# NUC123AE_v1 register map
File version: 1.0
Registers are 32-bit, read-write, reset 0x0 unless marked. A register's access mark holds for its fields unless they carry their own. Offsets are from the block's base; [hi:lo] are bit positions; lines under a group give offsets from that group; {n}, {i} and the like mark numbered series; 'fields as' and 'values as' point back to an identical list.

## PWMA — PWMA Register Map
Base 0x40040000
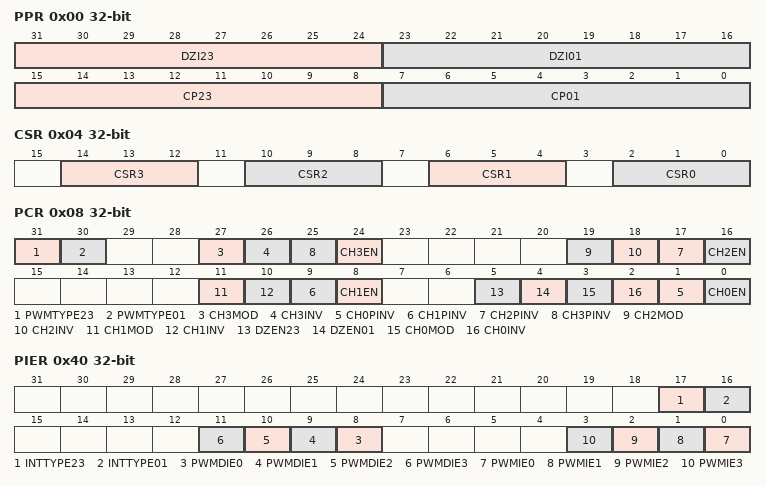
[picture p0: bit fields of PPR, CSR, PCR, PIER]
0x00 PPR — PWM Group A Pre-scale Register
  [31:24] DZI23 — Dead-zone Interval for Pair of Channel2 and Channel3 (PWM2 and PWM3 Pair for PWM Group A). These 8 bits determine dead-zone length. The unit time of dead-zone length is received from corresponding CSR bits.
  [23:16] DZI01 — Dead-zone Interval for Pair of Channel 0 and Channel 1 (PWM0 and PWM1 Pair for PWM Group A). These 8 bits determine dead-zone length. The unit time of dead-zone length is received from corresponding CSR bits.
  [15:8] CP23 — Clock Prescaler 2 (PWM Timer2 / 3 for Group A). Clock input is divided by (CP23 + 1) before it is fed to the corresponding PWM-timer.
  [7:0] CP01 — Clock Prescaler 0 (PWM-timer 0 / 1 for Group A). Clock input is divided by (CP01 + 1) before it is fed to the corresponding PWM-timer.
0x04 CSR — PWM Group A Clock Selector Register
  [14:12] CSR3 — PWM Timer 3 Clock Source Selection (PWM timer 3 for group A and PWM timer 7 for group B)
  [10:8] CSR2 — PWM Timer 2 Clock Source Selection (PWM Timer 2 for Group A and PWM Timer 6 for Group B). Select clock input for PWM timer. (Table is the same as CSR3.)
  [6:4] CSR1 — PWM Timer 1 Clock Source Selection (PWM Timer 1 for Group A and PWM Timer 5 for Group B). Select clock input for PWM timer. (Table is the same as CSR3.)
  [2:0] CSR0 — PWM Timer 0 Clock Source Selection (PWM Timer 0 for Group A and PWM Timer 4 for Group B). Select clock input for PWM timer. (Table is the same as CSR3.)
0x08 PCR — PWM Group A Control Register
  [31] PWMTYPE23 — PWM23 Aligned Type Selection Bit (PWM2 and PWM3 Pair for PWM Group A)
    0=Edge-aligned type; 1=Center-aligned type
  [30] PWMTYPE01 — PWM01 Aligned Type Selection Bit (PWM0 and PWM1 Pair for PWM Group A)
    0=Edge-aligned type; 1=Center-aligned type
  [27] CH3MOD — PWM-Timer 3 Auto-reload/One-Shot Mode (PWM Timer 3 for Group A). Note: If there is a transition at this bit, it will cause CNR3 and CMR3 be clear.
    0=One-shot mode; 1=Auto-reload mode
  [26] CH3INV — PWM-Timer 3 Output Inverter Enable (PWM Timer 3 for Group A)
    0=Inverter Disabled; 1=Inverter Enabled
  [8n+1] CH{n}PINV (n=0..3) — PWM-Timer {n} Output Polar Inverse Enable (PWM Timer {n} for Group A)
    0=PWM{n} output polar inverse Disabled; 1=PWM{n} output polar inverse Enabled
  [24] CH3EN — PWM-Timer 3 Enable (PWM Timer 3 for Group A)
    0=Corresponding PWM-Timer Running Stopped; 1=Corresponding PWM-Timer Start Run Enabled
  [19] CH2MOD — PWM-Timer 2 Auto-reload/One-Shot Mode (PWM Timer 2 for Group A). Note: If there is a transition at this bit, it will cause CNR2 and CMR2 be clear.
    0=One-shot mode; 1=Auto-reload mode
  [18] CH2INV — PWM-Timer 2 Output Inverter Enable (PWM Timer 2 for Group A)
    0=Inverter Disabled; 1=Inverter Enabled
  [16] CH2EN — PWM-Timer 2 Enable (PWM Timer 2 for Group A)
    values as CH3EN
  [11] CH1MOD — PWM-Timer 1 Auto-reload/One-Shot Mode (PWM Timer 1 for Group A). Note: If there is a transition at this bit, it will cause CNR1 and CMR1 be clear.
    0=One-shot mode; 1=Auto-load mode
  [10] CH1INV — PWM-Timer 1 Output Inverter Enable (PWM Timer 1 for Group A and PWM Timer 5 for Group B)
    0=Inverter Disabled; 1=Inverter Enabled
  [8] CH1EN — PWM-Timer 1 Enable (PWM Timer 1 for Group A and PWM Timer 5 for Group B)
    values as CH3EN
  [5] DZEN23 — Dead-Zone 2 Generator Enable (PWM2 and PWM3 Pair for PWM Group A). Note: When dead-zone generator is enabled, the pair of PWM2 and PWM3 becomes a complementary pair for PWM group A and the pair of PWM6 and PWM7 becomes a complementary pair for PWM group B.
    0=Disabled; 1=Enabled
  [4] DZEN01 — Dead-Zone 0 Generator Enable (PWM0 and PWM1 Pair for PWM Group A ). Note: When dead-zone generator is enabled, the pair of PWM0 and PWM1 becomes a complementary pair for PWM group A.
    0=Disabled; 1=Enabled
  [3] CH0MOD — PWM-Timer 0 Auto-reload/One-Shot Mode (PWM Timer 0 for Group A). Note: If there is a transition at this bit, it will cause CNR0 and CMR0 be clear.
    0=One-shot mode; 1=Auto-reload mode
  [2] CH0INV — PWM-Timer 0 Output Inverter Enable (PWM Timer 0 for Group A)
    0=Inverter Disabled; 1=Inverter Enabled
  [0] CH0EN — PWM-Timer 0 Enable (PWM timer 0 for group A)
    values as CH3EN
{0xC+0xC*i} CNR{i} (i=0..3) — PWM Group A Counter Register {i}
  [15:0] CNRx — PWM Timer Loaded Value. CNR determines the PWM period. Note: Any write to CNR will take effect in the next PWM cycle. Note: When PWM operating at center-aligned type, CNR value should be set between 0x0000 to 0xFFFE. If CNR equal to 0xFFFF, the PWM will work unpredictable. Note: When CNR value is set to 0, PWM output is always high.
{0x10+0xC*i} CMR{i} (i=0..3) — PWM Group A Comparator Register {i}
  [15:0] CMRx — PWM Comparator Register. CMR determines the PWM duty. Note: Any write to CNR will take effect in the next PWM cycle.
{0x14+0xC*i} PDR{i} ro (i=0..3) — PWM Group A Data Register {i}
  [15:0] PDRx — PWM Data Register. User can monitor PDR to know the current value in 16-bit down counter.
0x3C PBCR — PWM Group A backward compatible Register
0x40 PIER — PWM Group A Interrupt Enable Register
  [17] INTTYPE23 — PWM12 Interrupt Type Selection Bit (PWM2 and PWM3 Pair for PWM Group A, PWM6 and PWM7 Pair for PWM Group B). Note: This bit is effective when PWM in central align mode only.
    0=PWMIFn will be set if PWM counter underflow; 1=PWMIFn will be set if PWM counter matches CNRn register
  [16] INTTYPE01 — PWM01 Interrupt Type Selection Bit (PWM0 and PWM1 Pair for PWM Group A). Note: This bit is effective when PWM in central align mode only.
    values as INTTYPE23
  [n+8] PWMDIE{n} (n=0..3) — PWM Channel {n} Duty Interrupt Enable
    0=Disabled; 1=Enabled
  [n] PWMIE{n} (n=0..3) — PWM Channel {n} Interrupt Enable
    0=Disabled; 1=Enabled
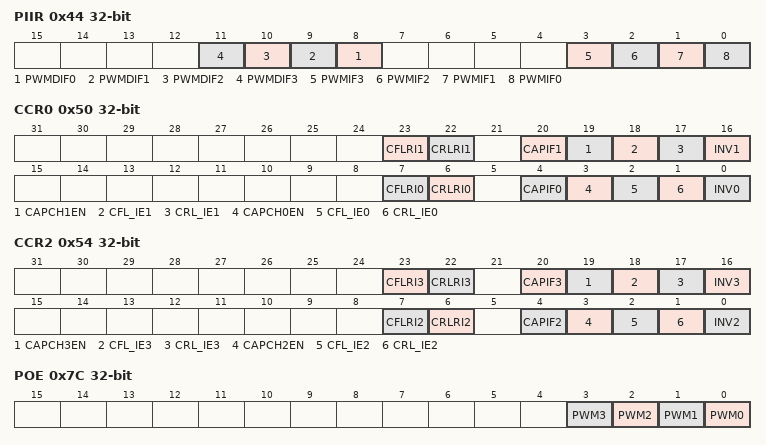
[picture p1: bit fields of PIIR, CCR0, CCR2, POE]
0x44 PIIR — PWM Group A Interrupt Indication Register
  [n+8] PWMDIF{n} (n=0..3) — PWM channel {n} Duty Interrupt Flag. Flag is set by hardware when channel {n} PWM counter down count and reaches CMR{n}, software can clear this bit by writing a one to it. Note: If CMR is equal to CNR, this flag is not working
  [3] PWMIF3 — PWM channel 3 Interrupt Status. This bit is set by hardware when PWM3 counter reaches the requirement of interrupt (depending on INTTYPE23 bit of PIER register) if PWM3 interrupt enable bit (PWMIE3) is 1, software can write 1 to clear this bit to zero
  [2] PWMIF2 — PWM channel 2 Interrupt Status. This bit is set by hardware when PWM2 counter reaches the requirement of interrupt (depending on INTTYPE23 bit of PIER register) if PWM2 interrupt enable bit (PWMIE2) is 1, software can write 1 to clear this bit to zero
  [1] PWMIF1 — PWM channel 1 Interrupt Status. This bit is set by hardware when PWM1 counter reaches the requirement of interrupt (depending on INTTYPE01 bit of PIER register) if PWM1 interrupt enable bit (PWMIE1) is 1, software can write 1 to clear this bit to zero
  [0] PWMIF0 — PWM channel 0 Interrupt Status. This bit is set by hardware when PWM0 counter reaches the requirement of interrupt (depending on INTTYPE01 bit of PIER register) if PWM0 interrupt enable bit (PWMIE0) is 1, software can write 1 to clear this bit to zero
0x50 CCR0 — PWM Group A Capture Control Register 0
  [23] CFLRI1 — CFLR1 Latched Indicator Bit. When PWM group input channel 1 has a falling transition, CFLR1 is latched with the value of PWM down-counter and this bit is set by hardware. Software can write 1 to clear this bit to zero.
  [22] CRLRI1 — CRLR1 Latched Indicator Bit. When PWM group input channel 1 has a rising transition, CRLR1 is latched with the value of PWM down-counter and this bit is set by hardware. Software can write 1 to clear this bit to zero.
  [20] CAPIF1 — Channel 1 Capture Interrupt Indication Flag. Write 1 to clear this bit to zero
  [19] CAPCH1EN — Channel 1 Capture Function Enable. When Enabled, Capture latched the PWM-counter and saved to CRLR (Rising latch) and CFLR (Falling latch). When Disabled, Capture does not update CRLR and CFLR, and disable PWM group channel 1 Interrupt.
    0=Capture function on PWM group channel 1 Disabled; 1=Capture function on PWM group channel 1 Enabled
  [18] CFL_IE1 — Channel 1 Falling Latch Interrupt Enable. When Enabled, if Capture detects PWM group channel 1 has falling transition, capture issues an Interrupt.
    0=Falling latch interrupt Disabled; 1=Falling latch interrupt Enabled
  [17] CRL_IE1 — Channel 1 Rising Latch Interrupt Enable. When Enable, if Capture detects PWM group channel 1 has rising transition, capture issues an Interrupt.
    0=Rising latch interrupt Disabled; 1=Rising latch interrupt Enabled
  [16] INV1 — Channel 1 Inverter Enable
    0=Inverter Disabled; 1=Inverter Enabled. Reverse the input signal from GPIO before fed to Capture timer
  [7] CFLRI0 — CFLR0 Latched Indicator Bit. When PWM group input channel 0 has a falling transition, CFLR0 was latched with the value of PWM down-counter and this bit is set by hardware. Software can write 1 to clear this bit to zero.
  [6] CRLRI0 — CRLR0 Latched Indicator Bit. When PWM group input channel 0 has a rising transition, CRLR0 was latched with the value of PWM down-counter and this bit is set by hardware. Software can write 1 to clear this bit to zero.
  [4] CAPIF0 — Channel 0 Capture Interrupt Indication Flag. Write 1 to clear this bit to zero
  [3] CAPCH0EN — Channel 0 Capture Function Enable. When Enabled, Capture latched the PWM-counter value and saved to CRLR (Rising latch) and CFLR (Falling latch). When Disabled, capture does not update CRLR and CFLR, and disable PWM group channel 0 Interrupt.
    0=Capture function on PWM group channel 0 Disabled; 1=Capture function on PWM group channel 0 Enabled
  [2] CFL_IE0 — Channel 0 Falling Latch Interrupt Enable. When Enabled, if capture detects PWM group channel 0 has falling transition, capture issues an Interrupt.
    values as CFL_IE1
  [1] CRL_IE0 — Channel 0 Rising Latch Interrupt Enable. When Enabled, if capture detects PWM group channel 0 has rising transition, capture issues an Interrupt.
    values as CRL_IE1
  [0] INV0 — Channel 0 Inverter Enable
    values as INV1
0x54 CCR2 — PWM Group A Capture Control Register 2
  [23] CFLRI3 — CFLR3 Latched Indicator Bit. When PWM group input channel 3 has a falling transition, CFLR3 was latched with the value of PWM down-counter and this bit is set by hardware. Software can write 1 to clear this bit to zero.
  [22] CRLRI3 — CRLR3 Latched Indicator Bit. When PWM group input channel 3 has a rising transition, CRLR3 was latched with the value of PWM down-counter and this bit is set by hardware. Software can write 1 to clear this bit to zero.
  [20] CAPIF3 — Channel 3 Capture Interrupt Indication Flag. Write 1 to clear this bit to zero
  [19] CAPCH3EN — Channel 3 Capture Function Enable. When Enabled, capture latched the PWM-counter and saved to CRLR (Rising latch) and CFLR (Falling latch). When Disabled, capture does not update CRLR and CFLR, and disable PWM group channel 3 Interrupt.
    0=Capture function on PWM group channel 3 Disabled; 1=Capture function on PWM group channel 3 Enabled
  [18] CFL_IE3 — Channel 3 Falling Latch Interrupt Enable. When Enabled, if capture detects PWM group channel 3 has falling transition, capture issues an Interrupt.
    values as CCR0.CFL_IE1
  [17] CRL_IE3 — Channel 3 Rising Latch Interrupt Enable. When Enabled, if Capture detects PWM group channel 3 has rising transition, capture issues an Interrupt.
    values as CCR0.CRL_IE1
  [16] INV3 — Channel 3 Inverter Enable
    values as CCR0.INV1
  [7] CFLRI2 — CFLR2 Latched Indicator Bit. When PWM group input channel 2 has a falling transition, CFLR2 was latched with the value of PWM down-counter and this bit is set by hardware. Software can write 1 to clear this bit to zero.
  [6] CRLRI2 — CRLR2 Latched Indicator Bit. When PWM group input channel 2 has a rising transition, CRLR2 was latched with the value of PWM down-counter and this bit is set by hardware. Software can write 1 to clear this bit to zero.
  [4] CAPIF2 — Channel 2 Capture Interrupt Indication Flag. Write 1 to clear this bit to zero
  [3] CAPCH2EN — Channel 2 Capture Function Enable. When Enabled, capture latched the PWM-counter value and saved to CRLR (Rising latch) and CFLR (Falling latch). When Disabled, capture does not update CRLR and CFLR, and disable PWM group channel 2 Interrupt.
    0=Capture function on PWM group channel 2 Disabled; 1=Capture function on PWM group channel 2 Enabled
  [2] CFL_IE2 — Channel 2 Falling Latch Interrupt Enable. When Enabled, if capture detects PWM group channel 2 has falling transition, capture issues an Interrupt.
    values as CCR0.CFL_IE1
  [1] CRL_IE2 — Channel 2 Rising Latch Interrupt Enable. When Enabled, if Capture detects PWM group channel 2 has rising transition, Capture issues an Interrupt.
    values as CCR0.CRL_IE1
  [0] INV2 — Channel 2 Inverter Enable
    values as CCR0.INV1
{0x58+8i} CRLR{i} ro (i=0..3) — PWM Group A Capture Rising Latch Register (Channel {i})
  [15:0] CRLRx — Capture Rising Latch Register. Latch the PWM counter when Channel 0/1/2/3 has rising transition.
{0x5C+8i} CFLR{i} ro (i=0..3) — PWM Group A Capture Falling Latch Register (Channel {i})
  [15:0] CFLRx — Capture Falling Latch Register. Latch the PWM counter when Channel 01/2/3 has Falling transition.
0x78 CAPENR — PWM Group A Capture Input 0~3 Enable Register
  [3:0] CAPENR — Capture Input Enable Register. There are four capture inputs from pad. Bit0~Bit3 are used to control each input enable or disable. . CAPENR. Bit 3210 for PWM group A. Bit xxx1 ( Capture channel 0 is from pin PA.12. Bit xx1x ( Capture channel 1 is from pin PA.13. Bit x1xx ( Capture channel 2 is from pin PA.14. Bit 1xxx ( Capture channel 3 is from pin PA.15. Bit 3210 for PWM group B. Bit xxx1 ( Capture channel 0 is from pin PB.11. Bit xx1x ( Capture channel 1 is from pin PE.5. Bit x1xx ( Capture channel 2 is from pin PE.0. Bit 1xxx ( Capture channel 3 is from pin PE.1
    0=Disabled (PWMx multi-function pin input does not affect input capture function.); 1=Enabled (PWMx multi-function pin input will affect its input capture function.)
0x7C POE — PWM Group A Output Enable Register for channel 0~3
  [n] PWM{n} (n=0..3) — Channel {n} Output Enable Register. Note: The corresponding GPIO pin must also be switched to PWM function.
    0=PWM channel {n} output to pin Disabled; 1=PWM channel {n} output to pin Enabled
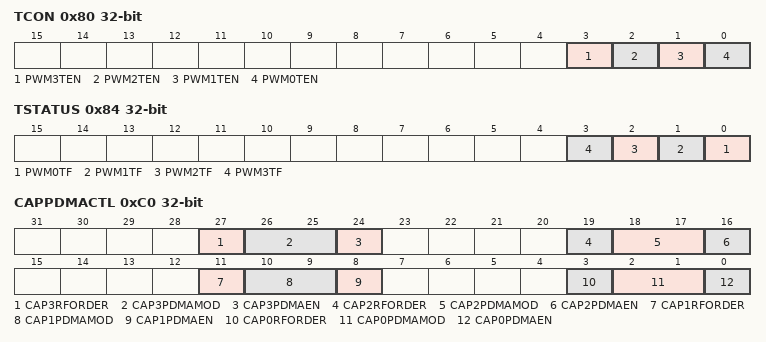
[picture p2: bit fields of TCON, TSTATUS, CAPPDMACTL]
0x80 TCON — PWM Group A Trigger Control Register for channel 0~3
  [3] PWM3TEN — Channel 3 Center-Aligned Trigger Enable Register. PWM can trigger ADC to start conversion when PWM counter counts up to CNR if this bit is set to 1. Note: This function is only supported when PWM operating in Center-aligned mode.
    0=PWM channel 3 trigger ADC function Disabled; 1=PWM channel 3 trigger ADC function Enabled
  [2] PWM2TEN — Channel 2 Center-Aligned Trigger Enable Register. PWM can trigger ADC to start conversion when PWM counter counts up to CNR if this bit is set to 1. Note: This function is only supported when PWM operating in Center-aligned mode.
    0=PWM channel 2 trigger ADC function Disabled; 1=PWM channel 2 trigger ADC function Enabled
  [1] PWM1TEN — Channel 1 Center-Aligned Trigger Enable Register. PWM can trigger ADC to start conversion when PWM counter counts up to CNR if this bit is set to 1. Note: This function is only supported when PWM operating in Center-aligned mode
    0=PWM channel 1 trigger ADC function Disabled; 1=PWM channel 1 trigger ADC function Enabled
  [0] PWM0TEN — Channel 0 Center-Aligned Trigger Enable Register. PWM can trigger ADC to start conversion when PWM counter counts up to CNR if this bit is set to 1. Note: This function is only supported when PWM operating in Center-aligned mode.
    0=PWM channel 0 trigger ADC function Disabled; 1=PWM channel 0 trigger ADC function Enabled
0x84 TSTATUS — PWM Group A Trigger Status Register
  [n] PWM{n}TF (n=0..3) — Channel {n} Center-aligned Trigger Flag. For Center-aligned operating mode, this bit is set to 1 by hardware when PWM counter up count to CNR if PWM{n}TEN bit is set to 1. After this bit is set to 1, ADC will start conversion if ADC triggered source is selected by PWM. Software can write 1 to clear this bit.
0x88 SYNCBUSY0 ro — PWM0 Group A Synchronous Busy Status Register
  [0] S_BUSY — PWM Synchronous Busy. When software writes CNR0/CMR0/PPR or switch PWM0 operation mode (PCR[3]), PWM will have a busy time to update these values completely because PWM clock may be different from system clock domain. Software needs to check this busy status before writes CNR0/CMR0/PPR or switch PWM0 operation mode (PCR[3]) to make sure previous setting has been update completely. This bit will be set when software write CNR0/CMR0/PPR or switch PWM0 operation mode (PCR[3]) and will be cleared by hardware automatically when PWM update these value completely.
0x8C SYNCBUSY1 ro — PWM1 Group A Synchronous Busy Status Register
  [0] S_BUSY — PWM Synchronous Busy. When software writes CNR1/CMR1/PPR or switches PWM1 operation mode (PCR[11]), PWM will have a busy time to update these values completely because PWM clock may be different from system clock domain. Software needs to check this busy status before writing CNR1/CMR1/PPR or switching PWM1 operation mode (PCR[11]) to make sure the previous setting has been updated completely. This bit will be set when software write CNR1/CMR1/PPR or switch PWM1 operation mode (PCR[11]) and will be cleared by hardware automatically when PWM updates these value completely.
0x90 SYNCBUSY2 ro — PWM2 Group A Synchronous Busy Status Register
  [0] S_BUSY — PWM Synchronous Busy. When software writes CNR2/CMR2/PPR or switch PWM2 operation mode (PCR[19]), PWM will have a busy time to update these values completely because PWM clock may be different from system clock domain. Software needs to check this busy status before writing CNR2/CMR2/PPR or switching PWM2 operation mode (PCR[19]) to make sure the previous setting has been updated completely. This bit will be set when software write CNR2/CMR2/PPR or switch PWM2 operation mode (PCR[19]) and will be cleared by hardware automatically when PWM updates these value completely.
0x94 SYNCBUSY3 ro — PWM3 Group A Synchronous Busy Status Register
  [0] S_BUSY — PWM Synchronous Busy. When software writes CNR3/CMR3/PPR or switch PWM3 operation mode (PCR[27]), PWM will have a busy time to update these values completely because PWM clock may be different from system clock domain. Software needs to check this busy status before writing CNR3/CMR3/PPR or switching PWM3 operation mode (PCR[27]) to make sure the previous setting has been updated completely. This bit will be set when software write CNR3/CMR3/PPR or switch PWM3 operation mode (PCR[27]) and will be cleared by hardware automatically when PWM updates these value completely.
0xC0 CAPPDMACTL — PWM Group A PDMA control register
  [27] CAP3RFORDER — Capture Channel 3 Rising/Falling Order
    0=CFLR3 is the first captured data to memory; 1=CRLR3 is the first captured data to memory
  [26:25] CAP3PDMAMOD — Select CRLR3 or CFLR3 to do PDMA Transfer
    1=CRLR3; 2=CFLR3; 3=Both CRLR3 and CFLR3
  [24] CAP3PDMAEN — Channel 3 PDMA enable
    0=Channel 3 PDMA function Disabled; 1=Channel 3 PDMA function Enabled for the channel 3 captured data and transfer to memory
  [19] CAP2RFORDER — Capture channel 2 Rising/Falling Order
    0=CFLR2 is the first captured data to memory; 1=CRLR2 is the first captured data to memory
  [18:17] CAP2PDMAMOD — Select CRLR2 or CFLR2 to do PDMA Transfer
    1=CRLR2; 2=CFLR2; 3=Both CRLR2 and CFLR2
  [16] CAP2PDMAEN — Channel 2 PDMA Enable
    0=Channel 2 PDMA function Disabled; 1=Channel 2 PDMA function Enabled for the channel 2 captured data and transfer to memory
  [11] CAP1RFORDER — Capture channel 1 Rising/Falling Order
    0=CFLR1 is the first captured data to memory; 1=CRLR1 is the first captured data to memory
  [10:9] CAP1PDMAMOD — Select CRLR1 or CFLR1 to Transfer PDMA
    1=CRLR1; 2=CFLR1; 3=both CRLR1 and CFLR1
  [8] CAP1PDMAEN — Channel 1 PDMA Enable
    0=Channel 1 PDMA function Disabled; 1=Channel 1 PDMA function Enabled for the channel 1 captured data and transfer to memory
  [3] CAP0RFORDER
    0=CFLR0 is the first captured data to memory; 1=CRLR0 is the first captured data to memory
  [2:1] CAP0PDMAMOD — Select CRLR0 or CFLR0 to Transfer PDMA
    1=CRLR0; 2=CFLR0; 3=Both CRLR0 and CFLR0
  [0] CAP0PDMAEN — Channel 0 PDMA Enable
    0=Channel 0 PDMA function Disabled; 1=Channel 0 PDMA function Enabled for the channel 0 captured data and transfer to memory
{0xC4+4i} CAP{i}PDMA ro (i=0..3) — PWM Group A PDMA channel {i} Data Register
  [15:0] CAP{i}RFPDMA — PDMA data register for channel {i} it is the capturing value(CFLR{i}/CRLR{i}) for channel {i}
